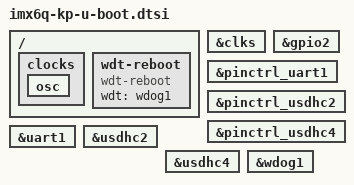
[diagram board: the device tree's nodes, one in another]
// SPDX-License-Identifier: GPL-2.0+
/*
 * Copyright 2019
 * Lukasz Majewski, DENX Software Engineering, lukma@denx.de
 *
 * SPDX-License-Identifier:     GPL-2.0+ or X11
 */

#include "imx6qdl-u-boot.dtsi"

/ {
	clocks {
		bootph-pre-ram;
		osc {
			bootph-pre-ram;
		};
	};

	wdt-reboot {
		compatible = "wdt-reboot";
		wdt = <&wdog1>;
	};
};

&clks {
	bootph-all;
};

&gpio2 {
	bootph-pre-ram;
};

&pinctrl_uart1 {
	bootph-pre-ram;
};

&pinctrl_usdhc2 {
	bootph-pre-ram;
};

&pinctrl_usdhc4 {
	bootph-pre-ram;
};

&uart1 {
	bootph-pre-ram;
};

&usdhc2 {
	bootph-pre-ram;
};

&usdhc4 {
	bootph-pre-ram;
};

&wdog1 {
	bootph-pre-ram;
};
